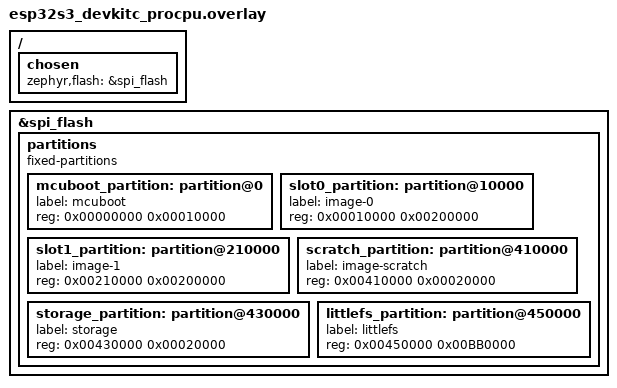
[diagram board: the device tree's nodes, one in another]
/ {
    chosen {
        zephyr,flash = &spi_flash;
    };
};

&spi_flash {
    partitions {
        compatible = "fixed-partitions";
        #address-cells = <1>;
        #size-cells = <1>;

        mcuboot_partition: partition@0 {
            label = "mcuboot";
            reg = <0x00000000 0x00010000>; /* 64 KB */
        };

        slot0_partition: partition@10000 {
            label = "image-0";
            reg = <0x00010000 0x00200000>; /* 2 MB */
        };

        slot1_partition: partition@210000 {
            label = "image-1";
            reg = <0x00210000 0x00200000>; /* 2 MB */
        };

        scratch_partition: partition@410000 {
            label = "image-scratch";
            reg = <0x00410000 0x00020000>; /* 128 KB */
        };

        storage_partition: partition@430000 {
            label = "storage";
            reg = <0x00430000 0x00020000>; /* 128 KB (NVS) */
        };

        littlefs_partition: partition@450000 {
            label = "littlefs";
            reg = <0x00450000 0x00BB0000>; /* remaining ~11.7 MB */
        };
    };
};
